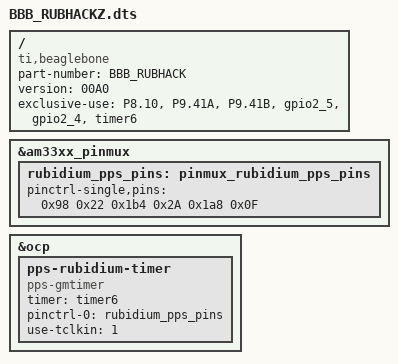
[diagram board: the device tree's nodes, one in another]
/*
 * Proto cape interfacing to Rubidium reference
 * Rubidium PPS on pin P8.10 (timer6 with TCLKIN)
 * Rubidium clock on pin P9.41
 * Note no GPS PPS, and Rubidium vs. Rubidium on timer6
 */
/dts-v1/;
/plugin/;

/ {
	compatible = "ti,beaglebone", "ti,beaglebone-black";

        /* identification */
        part-number = "BBB_RUBHACK";
        version = "00A0";

        /* state the resources this cape uses */
        exclusive-use =
                /* the pin header uses */
                "P8.10",        /* timer6/Rubidium PPS   */
		"P9.41A",       /* TCLKIN   */
		"P9.41B",       /* tied to TCLKIN   */
                /* the hardware ip uses */
                "gpio2_5", /* 0-based counting */
                "gpio2_4", /* 0-based counting */
		"timer6";  /* 0-based counting */

        fragment@0 {
                target = <&am33xx_pinmux>;
                __overlay__ {
                        rubidium_pps_pins: pinmux_rubidium_pps_pins {
				pinctrl-single,pins = <
				      0x98 0x22 /* P8.10 MODE2 TIMER6 */
                                      0x1b4 0x2A /* P9.41A MODE2 TCLKIN */
                                      0x1a8 0x0F /* P9.41B MODE7 INPUT (high-Z, tied to P9.41A) - conflicts with HDMI */
				>;
			};
                };
        };

	fragment@1 {
		target = <&ocp>;
                __overlay__ {
			pps-rubidium-timer {
				compatible = "pps-gmtimer";
				status = "okay";
				timer = <&timer6>;
				pinctrl-names = "default";
				pinctrl-0 = <&rubidium_pps_pins>;
				use-tclkin = <1>;
			};
		};
	};
};
